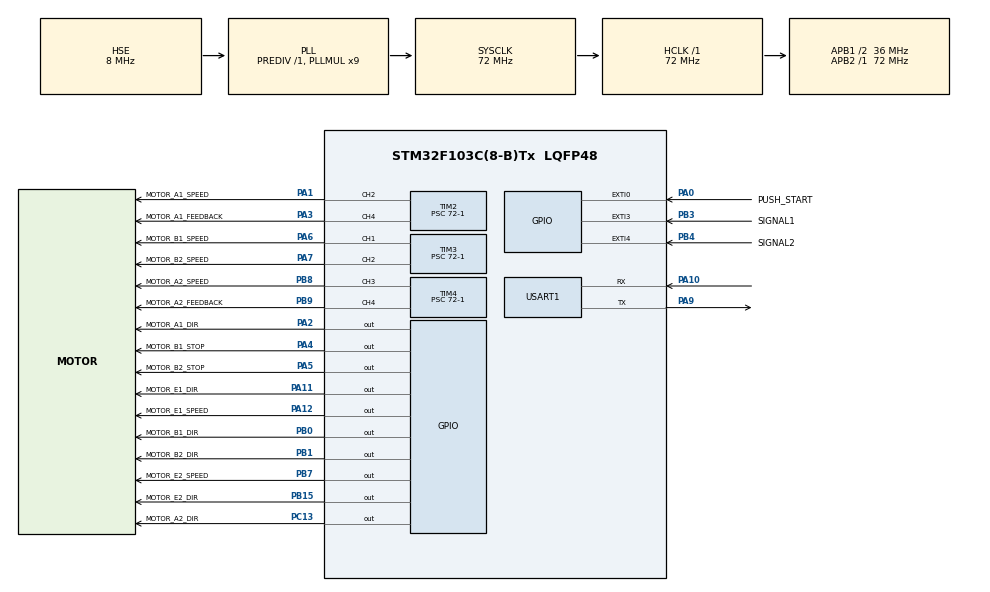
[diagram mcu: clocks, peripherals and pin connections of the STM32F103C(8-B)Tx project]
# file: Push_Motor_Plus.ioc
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Dma.Request0=USART1_TX
Dma.Request1=USART1_RX
Dma.USART1_RX.1.Direction=DMA_PERIPH_TO_MEMORY
Dma.USART1_RX.1.Instance=DMA1_Channel5
Dma.USART1_RX.1.MemDataAlignment=DMA_MDATAALIGN_BYTE
Dma.USART1_RX.1.MemInc=DMA_MINC_ENABLE
Dma.USART1_RX.1.Mode=DMA_CIRCULAR
Dma.USART1_RX.1.PeriphDataAlignment=DMA_PDATAALIGN_BYTE
Dma.USART1_RX.1.PeriphInc=DMA_PINC_DISABLE
Dma.USART1_RX.1.Priority=DMA_PRIORITY_LOW
Dma.USART1_TX.0.Direction=DMA_MEMORY_TO_PERIPH
Dma.USART1_TX.0.Instance=DMA1_Channel4
Dma.USART1_TX.0.MemDataAlignment=DMA_MDATAALIGN_BYTE
Dma.USART1_TX.0.MemInc=DMA_MINC_ENABLE
Dma.USART1_TX.0.Mode=DMA_NORMAL
Dma.USART1_TX.0.PeriphDataAlignment=DMA_PDATAALIGN_BYTE
Dma.USART1_TX.0.PeriphInc=DMA_PINC_DISABLE
Dma.USART1_TX.0.Priority=DMA_PRIORITY_LOW
Mcu.Family=STM32F1
Mcu.Name=STM32F103C(8-B)Tx
Mcu.Package=LQFP48
NVIC.DMA1_Channel4_IRQn=true\:0\:0\:true\:false\:true\:false\:true\:true
NVIC.DMA1_Channel5_IRQn=true\:0\:0\:true\:false\:true\:false\:true\:true
NVIC.EXTI0_IRQn=true\:0\:0\:false\:false\:true\:true\:true\:true
NVIC.PriorityGroup=NVIC_PRIORITYGROUP_4
NVIC.TIM1_UP_IRQn=true\:3\:0\:true\:false\:true\:true\:true\:true
NVIC.USART1_IRQn=true\:0\:0\:true\:false\:true\:true\:true\:true
PA0-WKUP.GPIO_Label=PUSH_START
PA0-WKUP.GPIO_ModeDefaultEXTI=GPIO_MODE_IT_RISING
PA0-WKUP.GPIO_PuPd=GPIO_PULLDOWN
PA0-WKUP.Signal=GPXTI0
PA1.GPIO_Label=MOTOR_A1_SPEED
PA1.Signal=S_TIM2_CH2
PA10.Mode=Asynchronous
PA10.Signal=USART1_RX
PA11.GPIO_Label=MOTOR_E1_DIR
PA11.Signal=GPIO_Output
PA12.GPIO_Label=MOTOR_E1_SPEED
PA12.GPIO_Speed=GPIO_SPEED_FREQ_HIGH
PA12.PinState=GPIO_PIN_SET
PA12.Signal=GPIO_Output
PA13.Mode=Serial_Wire
PA13.Signal=SYS_JTMS-SWDIO
PA14.Mode=Serial_Wire
PA14.Signal=SYS_JTCK-SWCLK
PA2.GPIO_Label=MOTOR_A1_DIR
PA2.Signal=GPIO_Output
PA3.GPIO_Label=MOTOR_A1_FEEDBACK
PA3.Signal=S_TIM2_CH4
PA4.GPIO_Label=MOTOR_B1_STOP
PA4.Signal=GPIO_Output
PA5.GPIO_Label=MOTOR_B2_STOP
PA5.Signal=GPIO_Output
PA6.GPIO_Label=MOTOR_B1_SPEED
PA6.Signal=S_TIM3_CH1
PA7.GPIO_Label=MOTOR_B2_SPEED
PA7.Signal=S_TIM3_CH2
PA9.Mode=Asynchronous
PA9.Signal=USART1_TX
PB0.GPIO_Label=MOTOR_B1_DIR
PB0.Signal=GPIO_Output
PB1.GPIO_Label=MOTOR_B2_DIR
PB1.Signal=GPIO_Output
PB15.GPIO_Label=MOTOR_E2_DIR
PB15.Signal=GPIO_Output
PB3.GPIO_Label=SIGNAL1
PB3.GPIO_ModeDefaultEXTI=GPIO_MODE_IT_RISING_FALLING
PB3.GPIO_PuPd=GPIO_PULLUP
PB3.Signal=GPXTI3
PB4.GPIO_Label=SIGNAL2
PB4.GPIO_ModeDefaultEXTI=GPIO_MODE_IT_RISING_FALLING
PB4.GPIO_PuPd=GPIO_PULLUP
PB4.Signal=GPXTI4
PB7.GPIO_Label=MOTOR_E2_SPEED
PB7.GPIO_Speed=GPIO_SPEED_FREQ_HIGH
PB7.PinState=GPIO_PIN_SET
PB7.Signal=GPIO_Output
PB8.GPIO_Label=MOTOR_A2_SPEED
PB8.Signal=S_TIM4_CH3
PB9.GPIO_Label=MOTOR_A2_FEEDBACK
PB9.Signal=S_TIM4_CH4
PC13-TAMPER-RTC.GPIO_Label=MOTOR_A2_DIR
PC13-TAMPER-RTC.Signal=GPIO_Output
PD0-OSC_IN.Mode=HSE-External-Oscillator
PD0-OSC_IN.Signal=RCC_OSC_IN
PD1-OSC_OUT.Mode=HSE-External-Oscillator
PD1-OSC_OUT.Signal=RCC_OSC_OUT
ProjectManager.HeapSize=0x200
ProjectManager.StackSize=0x400
ProjectManager.TargetToolchain=CMake
RCC.ADCPresc=RCC_ADCPCLK2_DIV6
RCC.AHBFreq_Value=72000000
RCC.APB1CLKDivider=RCC_HCLK_DIV2
RCC.APB1Freq_Value=36000000
RCC.APB1TimFreq_Value=72000000
RCC.APB2Freq_Value=72000000
RCC.APB2TimFreq_Value=72000000
RCC.HCLKFreq_Value=72000000
RCC.PLLMUL=RCC_PLL_MUL9
RCC.PLLSourceVirtual=RCC_PLLSOURCE_HSE
RCC.SYSCLKFreq_VALUE=72000000
RCC.SYSCLKSource=RCC_SYSCLKSOURCE_PLLCLK
RCC.USBFreq_Value=72000000
SH.S_TIM2_CH2.0=TIM2_CH2,PWM Generation2 CH2
SH.S_TIM2_CH4.0=TIM2_CH4,PWM Generation4 CH4
SH.S_TIM3_CH1.0=TIM3_CH1,PWM Generation1 CH1
SH.S_TIM3_CH2.0=TIM3_CH2,PWM Generation2 CH2
SH.S_TIM4_CH3.0=TIM4_CH3,PWM Generation3 CH3
SH.S_TIM4_CH4.0=TIM4_CH4,PWM Generation4 CH4
TIM1.AutoReloadPreload=TIM_AUTORELOAD_PRELOAD_ENABLE
TIM1.Period=180-1
TIM1.Prescaler=2-1
TIM2.Channel-PWM\ Generation2\ CH2=TIM_CHANNEL_2
TIM2.Channel-PWM\ Generation4\ CH4=TIM_CHANNEL_4
TIM2.Period=500-1
TIM2.Prescaler=72-1
TIM3.Channel-PWM\ Generation1\ CH1=TIM_CHANNEL_1
TIM3.Channel-PWM\ Generation2\ CH2=TIM_CHANNEL_2
TIM3.Period=500-1
TIM3.Prescaler=72-1
TIM4.Channel-PWM\ Generation3\ CH3=TIM_CHANNEL_3
TIM4.Channel-PWM\ Generation4\ CH4=TIM_CHANNEL_4
TIM4.Period=500-1
TIM4.Prescaler=72-1
USART1.VirtualMode=VM_ASYNC
VP_TIM1_VS_ClockSourceINT.Mode=Internal
VP_TIM2_VS_ClockSourceINT.Mode=Internal
VP_TIM3_VS_ClockSourceINT.Mode=Internal
VP_TIM4_VS_ClockSourceINT.Mode=Internal
board=custom

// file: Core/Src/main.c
/* USER CODE BEGIN Header */
/**
 ******************************************************************************
 * @file           : main.c
 * @brief          : Main program body
 ******************************************************************************
 * @attention
 *
 * Copyright (c) 2026 STMicroelectronics.
 * All rights reserved.
 *
 * This software is licensed under terms that can be found in the LICENSE file
 * in the root directory of this software component.
 * If no LICENSE file comes with this software, it is provided AS-IS.
 *
 ******************************************************************************
 */
/* USER CODE END Header */
#include "main.h"
#include "dma.h"
#include "tim.h"
#include "usart.h"
#include "gpio.h"

/* USER CODE BEGIN Includes */
#include "cli.h"
#include "pusher_motor.h"
/* USER CODE END Includes */

void SystemClock_Config(void);

int main(void)
{

  /* MCU Configuration--------------------------------------------------------*/

  /* Reset of all peripherals, Initializes the Flash interface and the Systick. */
  HAL_Init();

  /* Configure the system clock */
  SystemClock_Config();

  /* Initialize all configured peripherals */
  MX_GPIO_Init();
  MX_DMA_Init();
  MX_TIM2_Init();
  MX_TIM3_Init();
  MX_TIM4_Init();
  MX_USART1_UART_Init();
  MX_TIM1_Init();
  /* USER CODE BEGIN 2 */
  pusher_motor_init();
  cli_init(&huart1);

  /* USER CODE END 2 */

  /* Infinite loop */
  while (1)
  {

    /* USER CODE BEGIN 3 */
    cli_process();

    pusher_motor_loop();
  }
  /* USER CODE END 3 */
}

void SystemClock_Config(void)
{
  RCC_OscInitTypeDef RCC_OscInitStruct = {0};
  RCC_ClkInitTypeDef RCC_ClkInitStruct = {0};

  /** Initializes the RCC Oscillators according to the specified parameters
   * in the RCC_OscInitTypeDef structure.
   */
  RCC_OscInitStruct.OscillatorType = RCC_OSCILLATORTYPE_HSE;
  RCC_OscInitStruct.HSEState = RCC_HSE_ON;
  RCC_OscInitStruct.HSEPredivValue = RCC_HSE_PREDIV_DIV1;
  RCC_OscInitStruct.HSIState = RCC_HSI_ON;
  RCC_OscInitStruct.PLL.PLLState = RCC_PLL_ON;
  RCC_OscInitStruct.PLL.PLLSource = RCC_PLLSOURCE_HSE;
  RCC_OscInitStruct.PLL.PLLMUL = RCC_PLL_MUL9;
  if (HAL_RCC_OscConfig(&RCC_OscInitStruct) != HAL_OK)
  {
    Error_Handler();
  }

  /** Initializes the CPU, AHB and APB buses clocks
   */
  RCC_ClkInitStruct.ClockType = RCC_CLOCKTYPE_HCLK | RCC_CLOCKTYPE_SYSCLK | RCC_CLOCKTYPE_PCLK1 | RCC_CLOCKTYPE_PCLK2;
  RCC_ClkInitStruct.SYSCLKSource = RCC_SYSCLKSOURCE_PLLCLK;
  RCC_ClkInitStruct.AHBCLKDivider = RCC_SYSCLK_DIV1;
  RCC_ClkInitStruct.APB1CLKDivider = RCC_HCLK_DIV2;
  RCC_ClkInitStruct.APB2CLKDivider = RCC_HCLK_DIV1;

  if (HAL_RCC_ClockConfig(&RCC_ClkInitStruct, FLASH_LATENCY_2) != HAL_OK)
  {
    Error_Handler();
  }
}

void Error_Handler(void)
{
  __disable_irq();
  while (1)
  {
  }
}
